# STM32F107xx register map
File version: 1.2
CPU: 
Registers are 32-bit, read-write, reset 0x0 unless marked. A register's access mark holds for its fields unless they carry their own. Offsets are from the block's base; [hi:lo] are bit positions; {n}, {i} and the like mark numbered series.

## BKP — Backup registers
Base 0x40006C04
0x00 DR1 — Backup data register (BKP_DR)
  [15:0] D1 — Backup data
0x04 DR2 — Backup data register (BKP_DR)
  [15:0] D2 — Backup data
0x08 DR3 — Backup data register (BKP_DR)
  [15:0] D3 — Backup data
0x0C DR4 — Backup data register (BKP_DR)
  [15:0] D4 — Backup data
0x10 DR5 — Backup data register (BKP_DR)
  [15:0] D5 — Backup data
0x14 DR6 — Backup data register (BKP_DR)
  [15:0] D6 — Backup data
0x18 DR7 — Backup data register (BKP_DR)
  [15:0] D7 — Backup data
0x1C DR8 — Backup data register (BKP_DR)
  [15:0] D8 — Backup data
0x20 DR9 — Backup data register (BKP_DR)
  [15:0] D9 — Backup data
0x24 DR10 — Backup data register (BKP_DR)
  [15:0] D10 — Backup data
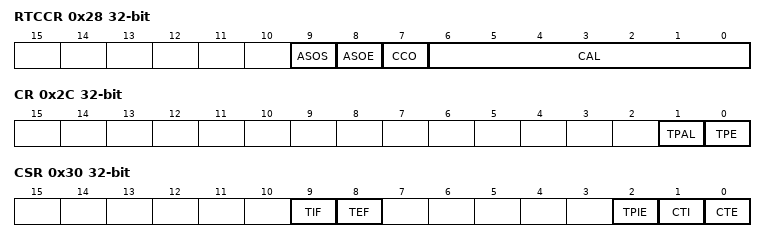
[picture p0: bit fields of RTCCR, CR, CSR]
0x28 RTCCR — RTC clock calibration register (BKP_RTCCR)
  [9] ASOS — Alarm or second output selection
  [8] ASOE — Alarm or second output enable
  [7] CCO — Calibration Clock Output
  [6:0] CAL — Calibration value
0x2C CR — Backup control register (BKP_CR)
  [1] TPAL — Tamper pin active level
  [0] TPE — Tamper pin enable
0x30 CSR access per field — BKP_CSR control/status register
  [9] TIF ro — Tamper Interrupt Flag
  [8] TEF ro — Tamper Event Flag
  [2] TPIE rw — Tamper Pin interrupt enable
  [1] CTI wo — Clear Tamper Interrupt
  [0] CTE wo — Clear Tamper event
{0x10+4i} DR{i} (i=11..13) — Backup data register (BKP_DR)
  [15:0] DR{i} — Backup data
{0x10+4i} DR{i} (i=14..42) — Backup data register (BKP_DR)
  [15:0] D{i} — Backup data

## IWDG — Independent watchdog
Base 0x40003000
0x00 KR wo — Key register (IWDG_KR)
  [15:0] KEY — Key value
0x04 PR — Prescaler register (IWDG_PR)
  [2:0] PR — Prescaler divider
0x08 RLR reset 0xFFF — Reload register (IWDG_RLR)
  [11:0] RL — Watchdog counter reload value
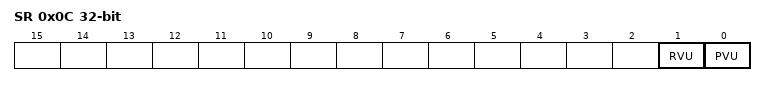
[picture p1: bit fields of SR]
0x0C SR ro — Status register (IWDG_SR)
  [1] RVU — Watchdog counter reload value update
  [0] PVU — Watchdog prescaler value update

## WWDG — Window watchdog
Base 0x40002C00
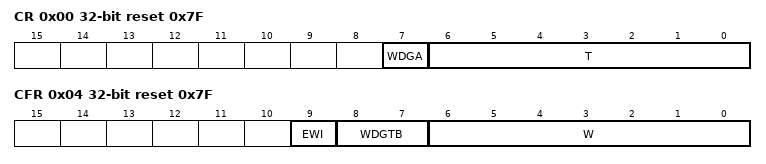
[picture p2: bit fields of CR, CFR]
0x00 CR reset 0x7F — Control register (WWDG_CR)
  [7] WDGA — Activation bit
  [6:0] T — 7-bit counter (MSB to LSB)
0x04 CFR reset 0x7F — Configuration register (WWDG_CFR)
  [9] EWI — Early Wakeup Interrupt
  [8:7] WDGTB — Timer Base
  [6:0] W — 7-bit window value
0x08 SR — Status register (WWDG_SR)
  [0] EWI — Early Wakeup Interrupt

## TIM6 — Basic timer
Base 0x40001000
Same registers: TIM7 0x40001400
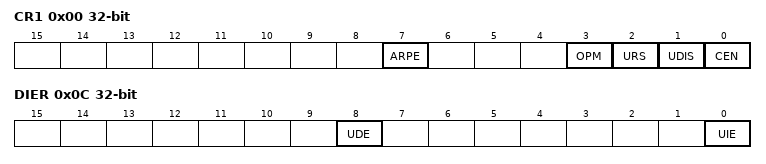
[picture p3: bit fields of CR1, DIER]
0x00 CR1 — control register 1
  [7] ARPE — Auto-reload preload enable
  [3] OPM — One-pulse mode
  [2] URS — Update request source
  [1] UDIS — Update disable
  [0] CEN — Counter enable
0x04 CR2 — control register 2
  [6:4] MMS — Master mode selection
0x0C DIER — DMA/Interrupt enable register
  [8] UDE — Update DMA request enable
  [0] UIE — Update interrupt enable
0x10 SR — status register
  [0] UIF — Update interrupt flag
0x14 EGR wo — event generation register
  [0] UG — Update generation
0x24 CNT — counter
  [15:0] CNT — Low counter value
0x28 PSC — prescaler
  [15:0] PSC — Prescaler value
0x2C ARR — auto-reload register
  [15:0] ARR — Low Auto-reload value

## I2C1 — Inter integrated circuit
Base 0x40005400
Same registers: I2C2 0x40005800
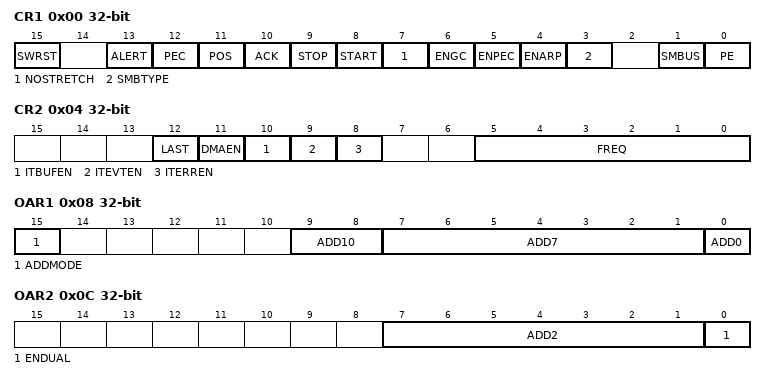
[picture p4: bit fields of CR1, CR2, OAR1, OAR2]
0x00 CR1 — Control register 1
  [15] SWRST — Software reset
  [13] ALERT — SMBus alert
  [12] PEC — Packet error checking
  [11] POS — Acknowledge/PEC Position (for data reception)
  [10] ACK — Acknowledge enable
  [9] STOP — Stop generation
  [8] START — Start generation
  [7] NOSTRETCH — Clock stretching disable (Slave mode)
  [6] ENGC — General call enable
  [5] ENPEC — PEC enable
  [4] ENARP — ARP enable
  [3] SMBTYPE — SMBus type
  [1] SMBUS — SMBus mode
  [0] PE — Peripheral enable
0x04 CR2 — Control register 2
  [12] LAST — DMA last transfer
  [11] DMAEN — DMA requests enable
  [10] ITBUFEN — Buffer interrupt enable
  [9] ITEVTEN — Event interrupt enable
  [8] ITERREN — Error interrupt enable
  [5:0] FREQ — Peripheral clock frequency
0x08 OAR1 — Own address register 1
  [15] ADDMODE — Addressing mode (slave mode)
  [9:8] ADD10 — Interface address
  [7:1] ADD7 — Interface address
  [0] ADD0 — Interface address
0x0C OAR2 — Own address register 2
  [7:1] ADD2 — Interface address
  [0] ENDUAL — Dual addressing mode enable
0x10 DR — Data register
  [7:0] DR — 8-bit data register
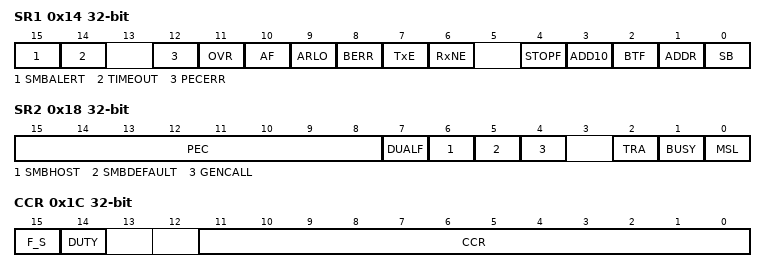
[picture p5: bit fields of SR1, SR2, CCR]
0x14 SR1 access per field — Status register 1
  [15] SMBALERT rw — SMBus alert
  [14] TIMEOUT rw — Timeout or Tlow error
  [12] PECERR rw — PEC Error in reception
  [11] OVR rw — Overrun/Underrun
  [10] AF rw — Acknowledge failure
  [9] ARLO rw — Arbitration lost (master mode)
  [8] BERR rw — Bus error
  [7] TxE ro — Data register empty (transmitters)
  [6] RxNE ro — Data register not empty (receivers)
  [4] STOPF ro — Stop detection (slave mode)
  [3] ADD10 ro — 10-bit header sent (Master mode)
  [2] BTF ro — Byte transfer finished
  [1] ADDR ro — Address sent (master mode)/matched (slave mode)
  [0] SB ro — Start bit (Master mode)
0x18 SR2 ro — Status register 2
  [15:8] PEC — acket error checking register
  [7] DUALF — Dual flag (Slave mode)
  [6] SMBHOST — SMBus host header (Slave mode)
  [5] SMBDEFAULT — SMBus device default address (Slave mode)
  [4] GENCALL — General call address (Slave mode)
  [2] TRA — Transmitter/receiver
  [1] BUSY — Bus busy
  [0] MSL — Master/slave
0x1C CCR — Clock control register
  [15] F_S — I2C master mode selection
  [14] DUTY — Fast mode duty cycle
  [11:0] CCR — Clock control register in Fast/Standard mode (Master mode)
0x20 TRISE reset 0x2
  [5:0] TRISE — Maximum rise time in Fast/Standard mode (Master mode)
